# STM32F103xE register map
File version: 1.0
Registers are 32-bit, read-write, reset 0x0 unless marked. A register's access mark holds for its fields unless they carry their own. Offsets are from the block's base; [hi:lo] are bit positions; {n}, {i} and the like mark numbered series.

## DAC — Digital to Analog Converter
Base 0x40007400
Same registers: DAC1 0x40007400 (alternate view of DAC)
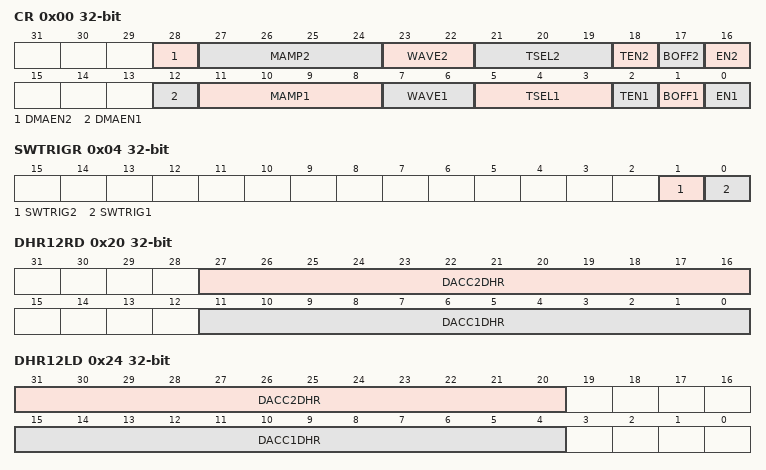
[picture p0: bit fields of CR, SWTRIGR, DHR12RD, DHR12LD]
0x00 CR
  [28] DMAEN2 — DAC channel2 DMA enabled
  [27:24] MAMP2 — MAMP2[3:0] (DAC channel2 Mask/Amplitude selector)
  [23:22] WAVE2 — WAVE2[1:0] (DAC channel2 noise/triangle wave generation enable)
  [21:19] TSEL2 — TSEL2[2:0] (DAC channel2 Trigger selection)
  [18] TEN2 — DAC channel2 Trigger enable
  [17] BOFF2 — DAC channel2 output buffer disable
  [16] EN2 — DAC channel2 enable
  [12] DMAEN1 — DAC channel1 DMA enable
  [11:8] MAMP1 — MAMP1[3:0] (DAC channel1 Mask/Amplitude selector)
  [7:6] WAVE1 — WAVE1[1:0] (DAC channel1 noise/triangle wave generation enable)
  [5:3] TSEL1 — TSEL1[2:0] (DAC channel1 Trigger selection)
  [2] TEN1 — DAC channel1 Trigger enable
  [1] BOFF1 — DAC channel1 output buffer disable
  [0] EN1 — DAC channel1 enable
0x04 SWTRIGR
  [1] SWTRIG2 — DAC channel2 software trigger
  [0] SWTRIG1 — DAC channel1 software trigger
0x08 DHR12R1
  [11:0] DACC1DHR — DAC channel1 12-bit Right aligned data
0x0C DHR12L1
  [15:4] DACC1DHR — DAC channel1 12-bit Left aligned data
0x10 DHR8R1
  [7:0] DACC1DHR — DAC channel1 8-bit Right aligned data
0x14 DHR12R2
  [11:0] DACC2DHR — DAC channel2 12-bit Right aligned data
0x18 DHR12L2
  [15:4] DACC2DHR — DAC channel2 12-bit Left aligned data
0x1C DHR8R2
  [7:0] DACC2DHR — DAC channel2 8-bit Right aligned data
0x20 DHR12RD
  [27:16] DACC2DHR — DAC channel2 12-bit Right aligned data
  [11:0] DACC1DHR — DAC channel1 12-bit Right aligned data
0x24 DHR12LD
  [31:20] DACC2DHR — DAC channel2 12-bit Left aligned data
  [15:4] DACC1DHR — DAC channel1 12-bit Left aligned data
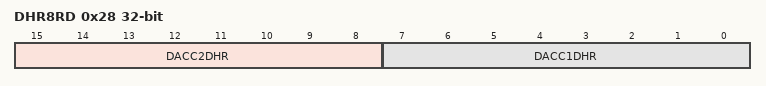
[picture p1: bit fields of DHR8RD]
0x28 DHR8RD
  [15:8] DACC2DHR — DAC channel2 8-bit Right aligned data
  [7:0] DACC1DHR — DAC channel1 8-bit Right aligned data
0x2C DOR1
  [11:0] DACC1DOR — DAC channel1 data output
0x30 DOR2
  [11:0] DACC2DOR — DAC channel2 data output

## AFIO — Alternate Function I/O
Base 0x40010000
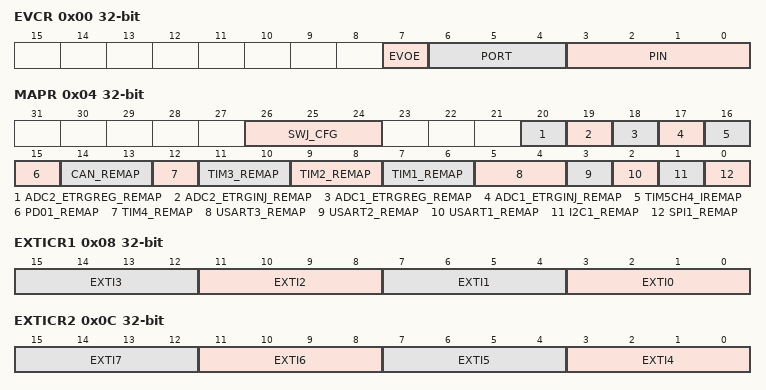
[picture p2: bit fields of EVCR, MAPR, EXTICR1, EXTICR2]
0x00 EVCR
  [7] EVOE — Event Output Enable
  [6:4] PORT — PORT[2:0] bits (Port selection)
  [3:0] PIN — PIN[3:0] bits (Pin selection)
0x04 MAPR
  [26:24] SWJ_CFG — SWJ_CFG[2:0] bits (Serial Wire JTAG configuration)
  [20] ADC2_ETRGREG_REMAP — ADC 2 External Trigger Regular Conversion remapping
  [19] ADC2_ETRGINJ_REMAP — ADC 2 External Trigger Injected Conversion remapping
  [18] ADC1_ETRGREG_REMAP — ADC 1 External Trigger Regular Conversion remapping
  [17] ADC1_ETRGINJ_REMAP — ADC 1 External Trigger Injected Conversion remapping
  [16] TIM5CH4_IREMAP — TIM5 Channel4 Internal Remap
  [15] PD01_REMAP — Port D0/Port D1 mapping on OSC_IN/OSC_OUT
  [14:13] CAN_REMAP — CAN_REMAP[1:0] bits (CAN Alternate function remapping)
  [12] TIM4_REMAP — TIM4_REMAP bit (TIM4 remapping)
  [11:10] TIM3_REMAP — TIM3_REMAP[1:0] bits (TIM3 remapping)
  [9:8] TIM2_REMAP — TIM2_REMAP[1:0] bits (TIM2 remapping)
  [7:6] TIM1_REMAP — TIM1_REMAP[1:0] bits (TIM1 remapping)
  [5:4] USART3_REMAP — USART3_REMAP[1:0] bits (USART3 remapping)
  [3] USART2_REMAP — USART2 remapping
  [2] USART1_REMAP — USART1 remapping
  [1] I2C1_REMAP — I2C1 remapping
  [0] SPI1_REMAP — SPI1 remapping
0x08 EXTICR1
  [4n+3:4n] EXTI{n} (n=0..3) — EXTI {n} configuration
0x0C EXTICR2
  [4n-13:4n-16] EXTI{n} (n=4..7) — EXTI {n} configuration
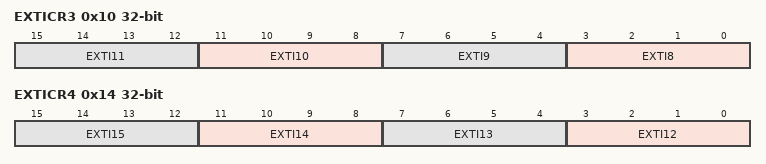
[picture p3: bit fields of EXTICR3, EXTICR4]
0x10 EXTICR3
  [4n-29:4n-32] EXTI{n} (n=8..11) — EXTI {n} configuration
0x14 EXTICR4
  [4n-45:4n-48] EXTI{n} (n=12..15) — EXTI {n} configuration
0x1C MAPR2
  [10] FSMC_NADV_REMAP — FSMC NADV remapping

## EXTI — External Interrupt/Event Controller
Base 0x40010400
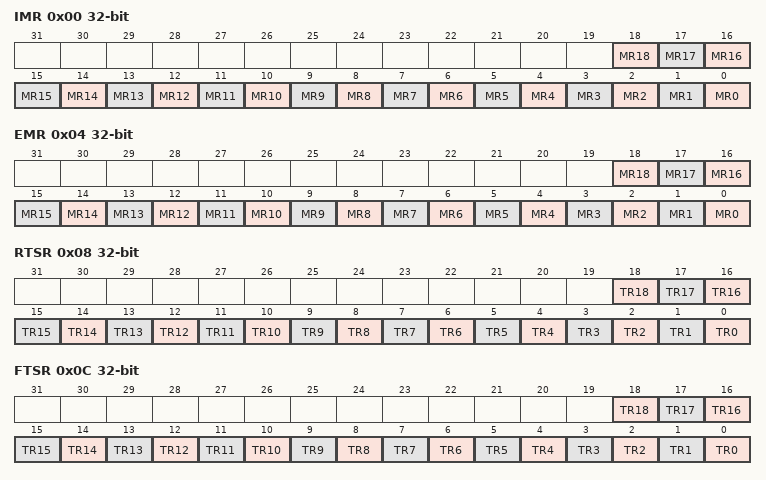
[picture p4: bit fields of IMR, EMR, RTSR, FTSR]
0x00 IMR
  [n] MR{n} (n=0..18) — Interrupt Mask on line {n}
0x04 EMR
  [n] MR{n} (n=0..18) — Event Mask on line {n}
0x08 RTSR
  [n] TR{n} (n=0..18) — Rising trigger event configuration bit of line {n}
0x0C FTSR
  [n] TR{n} (n=0..18) — Falling trigger event configuration bit of line {n}
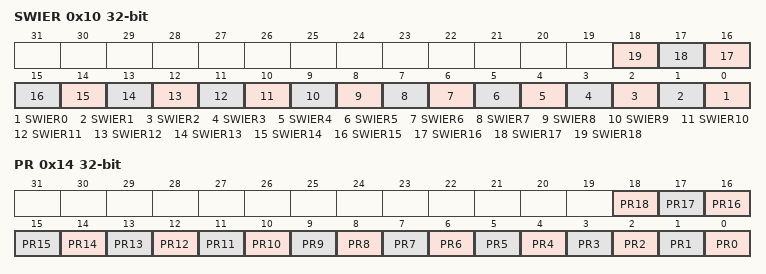
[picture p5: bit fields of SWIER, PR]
0x10 SWIER
  [n] SWIER{n} (n=0..18) — Software Interrupt on line {n}
0x14 PR
  [n] PR{n} (n=0..18) — Pending bit for line {n}
